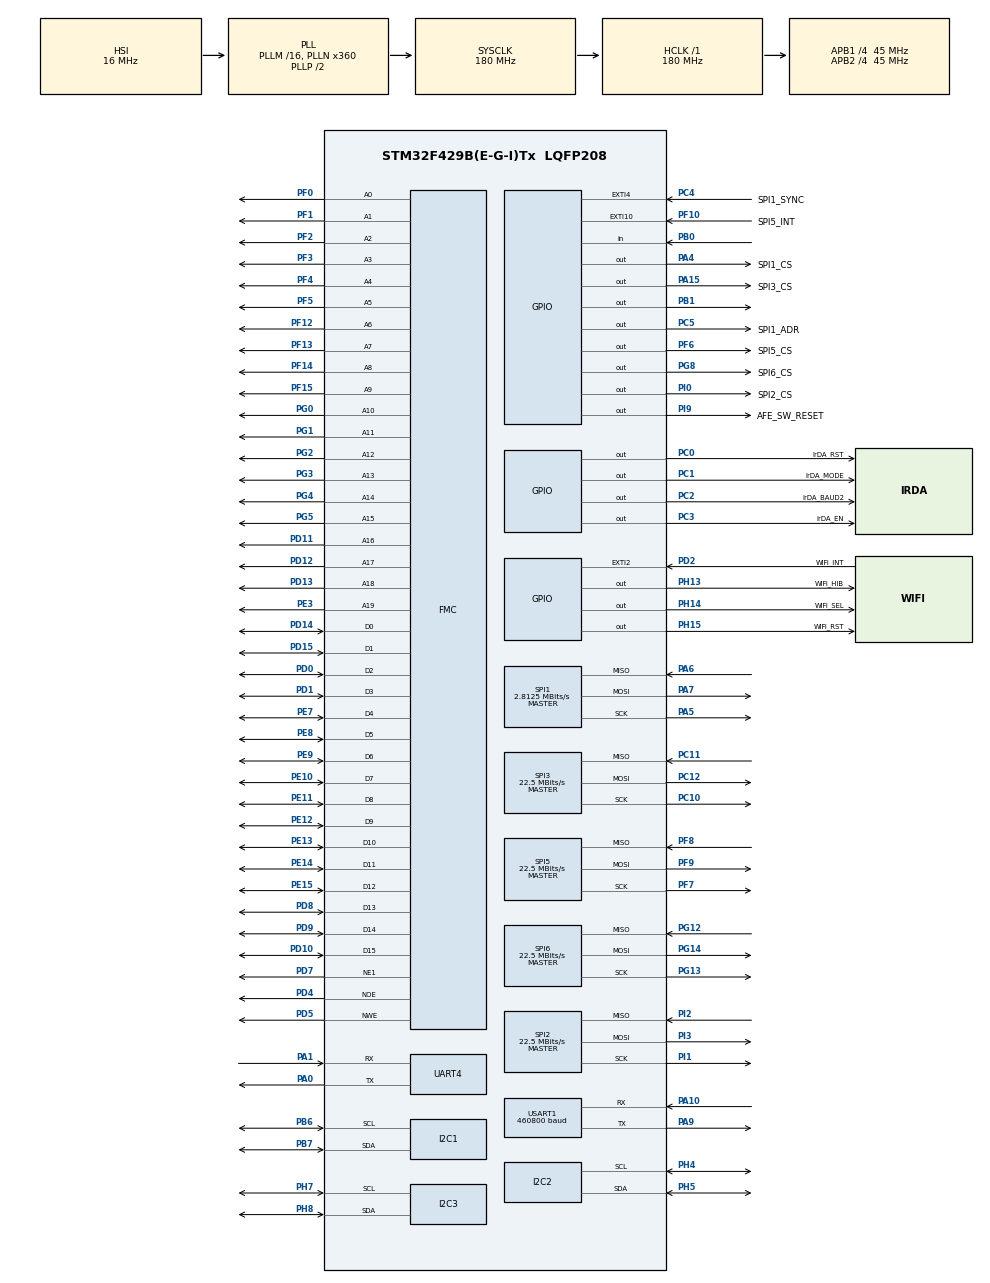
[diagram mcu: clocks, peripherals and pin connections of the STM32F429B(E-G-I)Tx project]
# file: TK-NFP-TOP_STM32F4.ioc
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Dma.I2C2_RX.0.Direction=DMA_PERIPH_TO_MEMORY
Dma.I2C2_RX.0.FIFOMode=DMA_FIFOMODE_DISABLE
Dma.I2C2_RX.0.Instance=DMA1_Stream3
Dma.I2C2_RX.0.MemDataAlignment=DMA_MDATAALIGN_BYTE
Dma.I2C2_RX.0.MemInc=DMA_MINC_ENABLE
Dma.I2C2_RX.0.Mode=DMA_NORMAL
Dma.I2C2_RX.0.PeriphDataAlignment=DMA_PDATAALIGN_BYTE
Dma.I2C2_RX.0.PeriphInc=DMA_PINC_DISABLE
Dma.I2C2_RX.0.Priority=DMA_PRIORITY_LOW
Dma.I2C2_TX.1.Direction=DMA_MEMORY_TO_PERIPH
Dma.I2C2_TX.1.FIFOMode=DMA_FIFOMODE_DISABLE
Dma.I2C2_TX.1.Instance=DMA1_Stream7
Dma.I2C2_TX.1.MemDataAlignment=DMA_MDATAALIGN_BYTE
Dma.I2C2_TX.1.MemInc=DMA_MINC_ENABLE
Dma.I2C2_TX.1.Mode=DMA_NORMAL
Dma.I2C2_TX.1.PeriphDataAlignment=DMA_PDATAALIGN_BYTE
Dma.I2C2_TX.1.PeriphInc=DMA_PINC_DISABLE
Dma.I2C2_TX.1.Priority=DMA_PRIORITY_HIGH
Dma.I2C3_RX.6.Direction=DMA_PERIPH_TO_MEMORY
Dma.I2C3_RX.6.FIFOMode=DMA_FIFOMODE_DISABLE
Dma.I2C3_RX.6.Instance=DMA1_Stream2
Dma.I2C3_RX.6.MemDataAlignment=DMA_MDATAALIGN_BYTE
Dma.I2C3_RX.6.MemInc=DMA_MINC_ENABLE
Dma.I2C3_RX.6.Mode=DMA_NORMAL
Dma.I2C3_RX.6.PeriphDataAlignment=DMA_PDATAALIGN_BYTE
Dma.I2C3_RX.6.PeriphInc=DMA_PINC_DISABLE
Dma.I2C3_RX.6.Priority=DMA_PRIORITY_HIGH
Dma.I2C3_TX.7.Direction=DMA_MEMORY_TO_PERIPH
Dma.I2C3_TX.7.FIFOMode=DMA_FIFOMODE_DISABLE
Dma.I2C3_TX.7.Instance=DMA1_Stream4
Dma.I2C3_TX.7.MemDataAlignment=DMA_MDATAALIGN_BYTE
Dma.I2C3_TX.7.MemInc=DMA_MINC_ENABLE
Dma.I2C3_TX.7.Mode=DMA_NORMAL
Dma.I2C3_TX.7.PeriphDataAlignment=DMA_PDATAALIGN_BYTE
Dma.I2C3_TX.7.PeriphInc=DMA_PINC_DISABLE
Dma.I2C3_TX.7.Priority=DMA_PRIORITY_LOW
Dma.Request0=I2C2_RX
Dma.Request1=I2C2_TX
Dma.Request2=USART1_RX
Dma.Request3=USART1_TX
Dma.Request4=SPI1_RX
Dma.Request5=SPI1_TX
Dma.Request6=I2C3_RX
Dma.Request7=I2C3_TX
Dma.SPI1_RX.4.Direction=DMA_PERIPH_TO_MEMORY
Dma.SPI1_RX.4.FIFOMode=DMA_FIFOMODE_DISABLE
Dma.SPI1_RX.4.Instance=DMA2_Stream0
Dma.SPI1_RX.4.MemDataAlignment=DMA_MDATAALIGN_BYTE
Dma.SPI1_RX.4.MemInc=DMA_MINC_ENABLE
Dma.SPI1_RX.4.Mode=DMA_NORMAL
Dma.SPI1_RX.4.PeriphDataAlignment=DMA_PDATAALIGN_BYTE
Dma.SPI1_RX.4.PeriphInc=DMA_PINC_DISABLE
Dma.SPI1_RX.4.Priority=DMA_PRIORITY_LOW
Dma.SPI1_TX.5.Direction=DMA_MEMORY_TO_PERIPH
Dma.SPI1_TX.5.FIFOMode=DMA_FIFOMODE_DISABLE
Dma.SPI1_TX.5.Instance=DMA2_Stream3
Dma.SPI1_TX.5.MemDataAlignment=DMA_MDATAALIGN_BYTE
Dma.SPI1_TX.5.MemInc=DMA_MINC_ENABLE
Dma.SPI1_TX.5.Mode=DMA_NORMAL
Dma.SPI1_TX.5.PeriphDataAlignment=DMA_PDATAALIGN_BYTE
Dma.SPI1_TX.5.PeriphInc=DMA_PINC_DISABLE
Dma.SPI1_TX.5.Priority=DMA_PRIORITY_LOW
Dma.USART1_RX.2.Direction=DMA_PERIPH_TO_MEMORY
Dma.USART1_RX.2.FIFOMode=DMA_FIFOMODE_DISABLE
Dma.USART1_RX.2.Instance=DMA2_Stream2
Dma.USART1_RX.2.MemDataAlignment=DMA_MDATAALIGN_BYTE
Dma.USART1_RX.2.MemInc=DMA_MINC_ENABLE
Dma.USART1_RX.2.Mode=DMA_NORMAL
Dma.USART1_RX.2.PeriphDataAlignment=DMA_PDATAALIGN_BYTE
Dma.USART1_RX.2.PeriphInc=DMA_PINC_DISABLE
Dma.USART1_RX.2.Priority=DMA_PRIORITY_LOW
Dma.USART1_TX.3.Direction=DMA_MEMORY_TO_PERIPH
Dma.USART1_TX.3.FIFOMode=DMA_FIFOMODE_DISABLE
Dma.USART1_TX.3.Instance=DMA2_Stream7
Dma.USART1_TX.3.MemDataAlignment=DMA_MDATAALIGN_BYTE
Dma.USART1_TX.3.MemInc=DMA_MINC_ENABLE
Dma.USART1_TX.3.Mode=DMA_NORMAL
Dma.USART1_TX.3.PeriphDataAlignment=DMA_PDATAALIGN_BYTE
Dma.USART1_TX.3.PeriphInc=DMA_PINC_DISABLE
Dma.USART1_TX.3.Priority=DMA_PRIORITY_HIGH
I2C2.I2C_Mode=I2C_Fast
I2C3.I2C_Mode=I2C_Fast
Mcu.Family=STM32F4
Mcu.Name=STM32F429B(E-G-I)Tx
Mcu.Package=LQFP208
NVIC.DMA1_Stream2_IRQn=true\:1\:0\:true\:false\:true\:false
NVIC.DMA1_Stream3_IRQn=true\:1\:3\:false\:false\:true\:false
NVIC.DMA1_Stream4_IRQn=true\:1\:1\:true\:false\:true\:false
NVIC.DMA1_Stream7_IRQn=true\:1\:2\:true\:false\:true\:false
NVIC.DMA2_Stream0_IRQn=true\:0\:0\:false\:false\:true\:false
NVIC.DMA2_Stream2_IRQn=true\:0\:1\:true\:false\:true\:false
NVIC.DMA2_Stream3_IRQn=true\:0\:0\:false\:false\:true\:false
NVIC.DMA2_Stream7_IRQn=true\:0\:0\:true\:false\:true\:false
NVIC.EXTI15_10_IRQn=true\:1\:0\:true\:false\:true\:true
NVIC.EXTI2_IRQn=true\:1\:0\:true\:false\:true\:true
NVIC.EXTI4_IRQn=true\:1\:0\:true\:false\:true\:true
NVIC.I2C2_EV_IRQn=true\:1\:0\:true\:false\:true\:true
NVIC.I2C3_EV_IRQn=true\:1\:0\:true\:false\:true\:true
NVIC.PriorityGroup=NVIC_PRIORITYGROUP_2
NVIC.SPI1_IRQn=true\:0\:0\:false\:false\:true\:true
NVIC.SPI5_IRQn=true\:1\:0\:true\:false\:true\:true
NVIC.SPI6_IRQn=true\:1\:0\:true\:false\:true\:true
NVIC.TIM1_TRG_COM_TIM11_IRQn=true\:1\:0\:true\:false\:true\:true
NVIC.TIM1_UP_TIM10_IRQn=true\:1\:0\:true\:false\:true\:true
NVIC.TIM7_IRQn=true\:1\:0\:true\:false\:true\:true
NVIC.TIM8_TRG_COM_TIM14_IRQn=true\:1\:0\:true\:false\:true\:true
NVIC.TIM8_UP_TIM13_IRQn=true\:1\:0\:true\:false\:true\:true
NVIC.UART4_IRQn=true\:1\:0\:true\:false\:true\:true
NVIC.USART1_IRQn=true\:1\:0\:true\:false\:true\:true
PA0/WKUP.Mode=Asynchronous
PA0/WKUP.Signal=UART4_TX
PA1.Mode=Asynchronous
PA1.Signal=UART4_RX
PA10.Mode=Asynchronous
PA10.Signal=USART1_RX
PA15.GPIO_Label=SPI3_CS
PA15.Signal=GPIO_Output
PA4.GPIO_Label=SPI1_CS
PA4.Signal=GPIO_Output
PA5.Mode=Full_Duplex_Master
PA5.Signal=SPI1_SCK
PA6.Mode=Full_Duplex_Master
PA6.Signal=SPI1_MISO
PA7.Mode=Full_Duplex_Master
PA7.Signal=SPI1_MOSI
PA9.Mode=Asynchronous
PA9.Signal=USART1_TX
PB0.Signal=GPIO_Input
PB1.Signal=GPIO_Output
PB6.Mode=I2C
PB6.Signal=I2C1_SCL
PB7.Mode=I2C
PB7.Signal=I2C1_SDA
PC0.GPIO_Label=IrDA_RST
PC0.Signal=GPIO_Output
PC1.GPIO_Label=IrDA_MODE
PC1.Signal=GPIO_Output
PC10.Mode=Full_Duplex_Master
PC10.Signal=SPI3_SCK
PC11.Mode=Full_Duplex_Master
PC11.Signal=SPI3_MISO
PC12.Mode=Full_Duplex_Master
PC12.Signal=SPI3_MOSI
PC2.GPIO_Label=IrDA_BAUD2
PC2.Signal=GPIO_Output
PC3.GPIO_Label=IrDA_EN
PC3.Signal=GPIO_Output
PC4.GPIO_Label=SPI1_SYNC
PC4.Signal=GPXTI4
PC5.GPIO_Label=SPI1_ADR
PC5.Signal=GPIO_Output
PD0.Signal=FMC_D2_DA2
PD1.Signal=FMC_D3_DA3
PD10.Signal=FMC_D15_DA15
PD11.Signal=FMC_A16_CLE
PD12.Signal=FMC_A17_ALE
PD13.Signal=FMC_A18
PD14.Signal=FMC_D0_DA0
PD15.Signal=FMC_D1_DA1
PD2.GPIO_Label=WiFi_INT
PD2.Signal=GPXTI2
PD4.Signal=FMC_NOE
PD5.Signal=FMC_NWE
PD7.Mode=NorPsramChipSelect1_1
PD7.Signal=FMC_NE1
PD8.Signal=FMC_D13_DA13
PD9.Signal=FMC_D14_DA14
PE10.Signal=FMC_D7_DA7
PE11.Signal=FMC_D8_DA8
PE12.Signal=FMC_D9_DA9
PE13.Signal=FMC_D10_DA10
PE14.Signal=FMC_D11_DA11
PE15.Signal=FMC_D12_DA12
PE3.Signal=FMC_A19
PE7.Signal=FMC_D4_DA4
PE8.Signal=FMC_D5_DA5
PE9.Signal=FMC_D6_DA6
PF0.Signal=FMC_A0
PF1.Signal=FMC_A1
PF10.GPIO_Label=SPI5_INT
PF10.Signal=GPXTI10
PF12.Signal=FMC_A6
PF13.Signal=FMC_A7
PF14.Signal=FMC_A8
PF15.Signal=FMC_A9
PF2.Signal=FMC_A2
PF3.Signal=FMC_A3
PF4.Signal=FMC_A4
PF5.Signal=FMC_A5
PF6.GPIO_Label=SPI5_CS
PF6.Signal=GPIO_Output
PF7.Mode=Full_Duplex_Master
PF7.Signal=SPI5_SCK
PF8.Mode=Full_Duplex_Master
PF8.Signal=SPI5_MISO
PF9.Mode=Full_Duplex_Master
PF9.Signal=SPI5_MOSI
PG0.Signal=FMC_A10
PG1.Signal=FMC_A11
PG12.Mode=Full_Duplex_Master
PG12.Signal=SPI6_MISO
PG13.Mode=Full_Duplex_Master
PG13.Signal=SPI6_SCK
PG14.Mode=Full_Duplex_Master
PG14.Signal=SPI6_MOSI
PG2.Signal=FMC_A12
PG3.Signal=FMC_A13
PG4.Signal=FMC_A14_BA0
PG5.Signal=FMC_A15_BA1
PG8.GPIO_Label=SPI6_CS
PG8.Signal=GPIO_Output
PH13.GPIO_Label=WiFi_HIB
PH13.Signal=GPIO_Output
PH14.GPIO_Label=WiFi_SEL
PH14.Signal=GPIO_Output
PH15.GPIO_Label=WiFi_RST
PH15.Signal=GPIO_Output
PH4.Mode=I2C
PH4.Signal=I2C2_SCL
PH5.Mode=I2C
PH5.Signal=I2C2_SDA
PH7.Mode=I2C
PH7.Signal=I2C3_SCL
PH8.Mode=I2C
PH8.Signal=I2C3_SDA
PI0.GPIO_Label=SPI2_CS
PI0.Signal=GPIO_Output
PI1.Mode=Full_Duplex_Master
PI1.Signal=SPI2_SCK
PI2.Mode=Full_Duplex_Master
PI2.Signal=SPI2_MISO
PI3.Mode=Full_Duplex_Master
PI3.Signal=SPI2_MOSI
PI9.GPIO_Label=AFE_SW_RESET
PI9.Signal=GPIO_Output
ProjectManager.HeapSize=0x200
ProjectManager.StackSize=0x400
ProjectManager.TargetToolchain=Other Toolchains (GPDSC)
RCC.48MHZClocksFreq_Value=90000000
RCC.AHBFreq_Value=180000000
RCC.APB1CLKDivider=RCC_HCLK_DIV4
RCC.APB1Freq_Value=45000000
RCC.APB1TimFreq_Value=90000000
RCC.APB2CLKDivider=RCC_HCLK_DIV4
RCC.APB2Freq_Value=45000000
RCC.APB2TimFreq_Value=90000000
RCC.CortexFreq_Value=180000000
RCC.HCLKFreq_Value=180000000
RCC.HSE_VALUE=25000000
RCC.HSI_VALUE=16000000
RCC.LSE_VALUE=32768
RCC.PLLN=360
RCC.SYSCLKFreq_VALUE=180000000
RCC.SYSCLKSource=RCC_SYSCLKSOURCE_PLLCLK
RCC.VCOOutputFreq_Value=360000000
SH.FMC_A0.0=FMC_A0,20b-a1
SH.FMC_A1.0=FMC_A1,20b-a1
SH.FMC_A10.0=FMC_A10,20b-a1
SH.FMC_A11.0=FMC_A11,20b-a1
SH.FMC_A12.0=FMC_A12,20b-a1
SH.FMC_A13.0=FMC_A13,20b-a1
SH.FMC_A14_BA0.0=FMC_A14,20b-a1
SH.FMC_A15_BA1.0=FMC_A15,20b-a1
SH.FMC_A16_CLE.0=FMC_A16,20b-a1
SH.FMC_A17_ALE.0=FMC_A17,20b-a1
SH.FMC_A18.0=FMC_A18,20b-a1
SH.FMC_A19.0=FMC_A19,20b-a1
SH.FMC_A2.0=FMC_A2,20b-a1
SH.FMC_A3.0=FMC_A3,20b-a1
SH.FMC_A4.0=FMC_A4,20b-a1
SH.FMC_A5.0=FMC_A5,20b-a1
SH.FMC_A6.0=FMC_A6,20b-a1
SH.FMC_A7.0=FMC_A7,20b-a1
SH.FMC_A8.0=FMC_A8,20b-a1
SH.FMC_A9.0=FMC_A9,20b-a1
SH.FMC_D0_DA0.0=FMC_D0,16b-d1
SH.FMC_D10_DA10.0=FMC_D10,16b-d1
SH.FMC_D11_DA11.0=FMC_D11,16b-d1
SH.FMC_D12_DA12.0=FMC_D12,16b-d1
SH.FMC_D13_DA13.0=FMC_D13,16b-d1
SH.FMC_D14_DA14.0=FMC_D14,16b-d1
SH.FMC_D15_DA15.0=FMC_D15,16b-d1
SH.FMC_D1_DA1.0=FMC_D1,16b-d1
SH.FMC_D2_DA2.0=FMC_D2,16b-d1
SH.FMC_D3_DA3.0=FMC_D3,16b-d1
SH.FMC_D4_DA4.0=FMC_D4,16b-d1
SH.FMC_D5_DA5.0=FMC_D5,16b-d1
SH.FMC_D6_DA6.0=FMC_D6,16b-d1
SH.FMC_D7_DA7.0=FMC_D7,16b-d1
SH.FMC_D8_DA8.0=FMC_D8,16b-d1
SH.FMC_D9_DA9.0=FMC_D9,16b-d1
SH.FMC_NOE.0=FMC_NOE,Sram1
SH.FMC_NWE.0=FMC_NWE,Sram1
SPI1.BaudRatePrescaler=SPI_BAUDRATEPRESCALER_16
SPI1.CLKPhase=SPI_PHASE_2EDGE
SPI1.CLKPolarity=SPI_POLARITY_HIGH
SPI1.CalculateBaudRate=2.8125 MBits/s
SPI1.Direction=SPI_DIRECTION_2LINES
SPI1.Mode=SPI_MODE_MASTER
SPI1.VirtualType=VM_MASTER
SPI2.BaudRatePrescaler=SPI_BAUDRATEPRESCALER_2
SPI2.CalculateBaudRate=22.5 MBits/s
SPI2.Direction=SPI_DIRECTION_2LINES
SPI2.Mode=SPI_MODE_MASTER
SPI2.VirtualType=VM_MASTER
SPI3.BaudRatePrescaler=SPI_BAUDRATEPRESCALER_2
SPI3.CalculateBaudRate=22.5 MBits/s
SPI3.Direction=SPI_DIRECTION_2LINES
SPI3.Mode=SPI_MODE_MASTER
SPI3.VirtualType=VM_MASTER
SPI5.BaudRatePrescaler=SPI_BAUDRATEPRESCALER_2
SPI5.CalculateBaudRate=22.5 MBits/s
SPI5.Direction=SPI_DIRECTION_2LINES
SPI5.Mode=SPI_MODE_MASTER
SPI5.VirtualType=VM_MASTER
SPI6.BaudRatePrescaler=SPI_BAUDRATEPRESCALER_2
SPI6.CalculateBaudRate=22.5 MBits/s
SPI6.Direction=SPI_DIRECTION_2LINES
SPI6.Mode=SPI_MODE_MASTER
SPI6.VirtualType=VM_MASTER
TIM10.Period=6
TIM10.Prescaler=45000
TIM11.Period=10000
TIM11.Prescaler=1300
TIM13.Period=100
TIM13.Prescaler=45000
TIM7.Period=500
TIM7.Prescaler=24
UART4.VirtualMode=Asynchronous
USART1.BaudRate=460800
USART1.VirtualMode=VM_ASYNC
VP_TIM10_VS_ClockSourceINT.Mode=Enable_Timer
VP_TIM11_VS_ClockSourceINT.Mode=Enable_Timer
VP_TIM13_VS_ClockSourceINT.Mode=Enable_Timer
VP_TIM14_VS_ClockSourceINT.Mode=Enable_Timer
VP_TIM7_VS_ClockSourceINT.Mode=Enable_Timer
board=TK-NFP-TOP_STM32F4

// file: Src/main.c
/**
  ******************************************************************************
  * @file           : main.c
  * @brief          : Main program body
  ******************************************************************************
  ** This notice applies to any and all portions of this file
  * that are not between comment pairs USER CODE BEGIN and
  * USER CODE END. Other portions of this file, whether
  * inserted by the user or by software development tools
  * are owned by their respective copyright owners.
  *
  * COPYRIGHT(c) 2018 STMicroelectronics
  *
  * Redistribution and use in source and binary forms, with or without modification,
  * are permitted provided that the following conditions are met:
  *   1. Redistributions of source code must retain the above copyright notice,
  *      this list of conditions and the following disclaimer.
  *   2. Redistributions in binary form must reproduce the above copyright notice,
  *      this list of conditions and the following disclaimer in the documentation
  *      and/or other materials provided with the distribution.
  *   3. Neither the name of STMicroelectronics nor the names of its contributors
  *      may be used to endorse or promote products derived from this software
  *      without specific prior written permission.
  *
  * THIS SOFTWARE IS PROVIDED BY THE COPYRIGHT HOLDERS AND CONTRIBUTORS "AS IS"
  * AND ANY EXPRESS OR IMPLIED WARRANTIES, INCLUDING, BUT NOT LIMITED TO, THE
  * IMPLIED WARRANTIES OF MERCHANTABILITY AND FITNESS FOR A PARTICULAR PURPOSE ARE
  * DISCLAIMED. IN NO EVENT SHALL THE COPYRIGHT HOLDER OR CONTRIBUTORS BE LIABLE
  * FOR ANY DIRECT, INDIRECT, INCIDENTAL, SPECIAL, EXEMPLARY, OR CONSEQUENTIAL
  * DAMAGES (INCLUDING, BUT NOT LIMITED TO, PROCUREMENT OF SUBSTITUTE GOODS OR
  * SERVICES; LOSS OF USE, DATA, OR PROFITS; OR BUSINESS INTERRUPTION) HOWEVER
  * CAUSED AND ON ANY THEORY OF LIABILITY, WHETHER IN CONTRACT, STRICT LIABILITY,
  * OR TORT (INCLUDING NEGLIGENCE OR OTHERWISE) ARISING IN ANY WAY OUT OF THE USE
  * OF THIS SOFTWARE, EVEN IF ADVISED OF THE POSSIBILITY OF SUCH DAMAGE.
  *
  ******************************************************************************
  */
#include "main.h"
#include "stm32f4xx_hal.h"
#include "dma.h"
#include "i2c.h"
#include "spi.h"
#include "tim.h"
#include "usart.h"
#include "gpio.h"
#include "fmc.h"

/* USER CODE BEGIN Includes */
#include "Handler.h"
#include "ExtFunctions.h"
#include "AD7190.h"

/* USER CODE END Includes */

/* USER CODE BEGIN PV */
/* Private variables ---------------------------------------------------------*/
uint8_t usart1BufRx[1];
uint8_t I2C2_TRANSMIT_STARTED = 0;
uint8_t I2C2_TRANSMIT_ENDED = 0;
/* USER CODE END PV */

void SystemClock_Config(void);

/* USER CODE BEGIN PFP */
/* Private function prototypes -----------------------------------------------*/

/* USER CODE END PFP */

int main(void)
{

  /* MCU Configuration----------------------------------------------------------*/

  /* Reset of all peripherals, Initializes the Flash interface and the Systick. */
  HAL_Init();

  /* Configure the system clock */
  SystemClock_Config();

  /* Initialize all configured peripherals */
  MX_GPIO_Init();
  MX_DMA_Init();
  MX_USART1_UART_Init();
  MX_UART4_Init();
  MX_SPI1_Init();
  MX_SPI2_Init();
  MX_SPI3_Init();
  MX_SPI5_Init();
  MX_SPI6_Init();
  MX_TIM14_Init();
  MX_TIM13_Init();
  MX_I2C1_Init();
  MX_I2C2_Init();
  MX_I2C3_Init();
  MX_FMC_Init();
  MX_TIM7_Init();
  MX_TIM10_Init();
  MX_TIM11_Init();
  /* USER CODE BEGIN 2 */
    SPI6_CS_UP
    InitHandler(POLYGRAPH);
    EEGRecorderInit(1,250);
    WriteMem(REG_LOG_LVL, 7);
    WriteMem(REG_Simple_link, 1);
    WriteMem(REG_EEG_Auto_Band, 0);
    WriteMem(REG_ADC_REG1,0x00000001);
    WriteMem(REG_ADC_REG2,0x00000001);
    WriteMem(REG_ADC_REG3,0x00000004);
    usart1BufRx[0] = 0x00;
    HAL_UART_Receive_DMA(&huart1, usart1BufRx, 1);
    HAL_TIM_Base_Start_IT(&htim7);
    HAL_TIM_Base_Start_IT(&htim10);
    HAL_TIM_Base_Start_IT(&htim11);

//    AD7190_Reset();
    unsigned long samplesAverage = 0x0;
    unsigned long chn = 0x0;
//    samplesAverage = AD7190_GetRegisterValue(AD7190_REG_STAT, 1, 1, 1);
//    chn=sprintf(buffer,"AD7190_REG_STAT %08X",samplesAverage);
//    HAL_UART_Transmit(&huart1, buffer, chn, 10000);
//    HAL_Delay(1000);
//    samplesAverage = AD7190_GetRegisterValue(AD7190_REG_MODE, 3, 1, 1);
//    chn=sprintf(buffer,"AD7190_REG_MODE %08X",samplesAverage);
//    HAL_UART_Transmit(&huart1, buffer, chn, 10000);
//    HAL_Delay(1000);
//    samplesAverage = AD7190_GetRegisterValue(AD7190_REG_CONF, 3, 1, 1);
//    chn=sprintf(buffer,"AD7190_REG_CONF %08X",samplesAverage);
//    HAL_UART_Transmit(&huart1, buffer, chn, 10000);
//    HAL_Delay(1000);
//    samplesAverage = AD7190_GetRegisterValue(AD7190_REG_DATA, 3, 1, 1);
//    chn=sprintf(buffer,"AD7190_REG_DATA %08X",samplesAverage);
//    HAL_UART_Transmit(&huart1, buffer, chn, 10000);
//    HAL_Delay(1000);
//    samplesAverage = AD7190_GetRegisterValue(AD7190_REG_ID, 1, 1, 1);
//    chn=sprintf(buffer,"AD7190_REG_ID %08X",samplesAverage);
//    HAL_UART_Transmit(&huart1, buffer, chn, 10000);
//    HAL_Delay(1000);
//    samplesAverage = AD7190_GetRegisterValue(AD7190_REG_GPOCON, 1, 1, 1);
//    chn=sprintf(buffer,"AD7190_REG_GPOCON %08X",samplesAverage);
//    HAL_UART_Transmit(&huart1, buffer, chn, 10000);
//    HAL_Delay(1000);
//    samplesAverage = AD7190_GetRegisterValue(AD7190_REG_OFFSET, 3, 1, 1);
//    chn=sprintf(buffer,"AD7190_REG_OFFSET %08X",samplesAverage);
//    HAL_UART_Transmit(&huart1, buffer, chn, 10000);
//    HAL_Delay(1000);
//    samplesAverage = AD7190_GetRegisterValue(AD7190_REG_FULLSCALE, 3, 1, 1);
//    chn=sprintf(buffer,"AD7190_REG_FULLSCALE %08X",samplesAverage);
//    HAL_UART_Transmit(&huart1, buffer, chn, 10000);
//    HAL_Delay(1000);

//    AD7190_SetPower(1);
    if (AD7190_Init() == 1)
    {
        AD7190_SetLeds(2);
        HAL_UART_Transmit(&huart1, "AD7190 found", 12, 10000);
    }
    else
    {
        AD7190_SetLeds(0);
        HAL_UART_Transmit(&huart1, "AD7190 not found", 16, 10000);
    }
//    HAL_SPI_Transmit_DMA(&hspi1, "-----", 5);
//    AD7190_RangeSetup(1,AD7190_CONF_GAIN_1);
//    AD7190_ChannelSelect(AD7190_CH_AIN1P_AINCOM);
//    CommandLineInterpreter("/get/memory?ip=192.168.1.3&port=5683");

//        HAL_UART_Transmit(&huart1, "test2", 5, 10000);
    WriteMem(REG_Led_Ch_T1,1);
    WriteMem(REG_Led_Ch_T2,2);
    WriteMem(REG_Led_Ch_T3,4);
    WriteMem(REG_Led_Q_T1_Red,100);
    WriteMem(REG_Led_Q_T1_Green,1);
    WriteMem(REG_Led_Q_T1_Blue,1);
    WriteMem(REG_Led_Q_T2_Red,1);
    WriteMem(REG_Led_Q_T2_Green,100);
    WriteMem(REG_Led_Q_T2_Blue,1);
    WriteMem(REG_Led_Q_T3_Red,1);
    WriteMem(REG_Led_Q_T3_Green,1);
    WriteMem(REG_Led_Q_T3_Blue,100);

    AFE_MUX_IMP_init();

  /* USER CODE END 2 */

  /* Infinite loop */
  /* USER CODE BEGIN WHILE */
//    AD7190_GetRegisterValue(AD7190_REG_ID, 1, 1, 0);
//    initiateConversionCycle();
//    HAL_SPI_Transmit_DMA(&hspi1, "-----", 5);
//    initiateDMATestCycle();
//    AD7190_SetLeds(2);
    AD7190_ContinuousReadStart();
    unsigned char i=0;
//    HAL_UART_Transmit(&huart1, "Check", 5, 10000);
//    HAL_Delay(1000);
//    samplesAverage = AD7190_GetRegisterValue(AD7190_REG_STAT, 1, 1, 1);
//    chn=sprintf(buffer,"AD7190_REG_STAT %08X",samplesAverage);
//    HAL_UART_Transmit(&huart1, buffer, chn, 10000);
//    HAL_Delay(1000);
//    samplesAverage = AD7190_GetRegisterValue(AD7190_REG_MODE, 3, 1, 1);
//    chn=sprintf(buffer,"AD7190_REG_MODE %08X",samplesAverage);
//    HAL_UART_Transmit(&huart1, buffer, chn, 10000);
//    HAL_Delay(1000);
//    samplesAverage = AD7190_GetRegisterValue(AD7190_REG_CONF, 3, 1, 1);
//    chn=sprintf(buffer,"AD7190_REG_CONF %08X",samplesAverage);
//    HAL_UART_Transmit(&huart1, buffer, chn, 10000);
//    HAL_Delay(1000);
//    samplesAverage = AD7190_GetRegisterValue(AD7190_REG_DATA, 3, 1, 1);
//    chn=sprintf(buffer,"AD7190_REG_DATA %08X",samplesAverage);
//    HAL_UART_Transmit(&huart1, buffer, chn, 10000);
//    HAL_Delay(1000);
//    samplesAverage = AD7190_GetRegisterValue(AD7190_REG_ID, 1, 1, 1);
//    chn=sprintf(buffer,"AD7190_REG_ID %08X",samplesAverage);
//    HAL_UART_Transmit(&huart1, buffer, chn, 10000);
//    HAL_Delay(1000);
//    samplesAverage = AD7190_GetRegisterValue(AD7190_REG_GPOCON, 1, 1, 1);
//    chn=sprintf(buffer,"AD7190_REG_GPOCON %08X",samplesAverage);
//    HAL_UART_Transmit(&huart1, buffer, chn, 10000);
//    HAL_Delay(1000);
//    samplesAverage = AD7190_GetRegisterValue(AD7190_REG_OFFSET, 3, 1, 1);
//    chn=sprintf(buffer,"AD7190_REG_OFFSET %08X",samplesAverage);
//    HAL_UART_Transmit(&huart1, buffer, chn, 10000);
//    HAL_Delay(1000);
//    samplesAverage = AD7190_GetRegisterValue(AD7190_REG_FULLSCALE, 3, 1, 1);
//    chn=sprintf(buffer,"AD7190_REG_FULLSCALE %08X",samplesAverage);
//    HAL_UART_Transmit(&huart1, buffer, chn, 10000);

    HAL_Delay(3000);
    HAL_TIM_Base_Start_IT(&htim14);
    HAL_UART_Transmit(&huart1, "\n\r\nStart!\n\r\n", 12, 1000);
    while (1)
    {
      UserOperationHandler();
      UserProtocolHandler();

//      if (observerConversionCycle())
//        initiateConversionCycle();

  /* USER CODE END WHILE */

  /* USER CODE BEGIN 3 */
//    WriteMem(REG_ADC_CH1,AD7190_ContinuousRead());
    }
  /* USER CODE END 3 */

}

void SystemClock_Config(void)
{

  RCC_OscInitTypeDef RCC_OscInitStruct;
  RCC_ClkInitTypeDef RCC_ClkInitStruct;

    /**Configure the main internal regulator output voltage
    */
  __HAL_RCC_PWR_CLK_ENABLE();

  __HAL_PWR_VOLTAGESCALING_CONFIG(PWR_REGULATOR_VOLTAGE_SCALE1);

    /**Initializes the CPU, AHB and APB busses clocks
    */
  RCC_OscInitStruct.OscillatorType = RCC_OSCILLATORTYPE_HSI;
  RCC_OscInitStruct.HSIState = RCC_HSI_ON;
  RCC_OscInitStruct.HSICalibrationValue = 16;
  RCC_OscInitStruct.PLL.PLLState = RCC_PLL_ON;
  RCC_OscInitStruct.PLL.PLLSource = RCC_PLLSOURCE_HSI;
  RCC_OscInitStruct.PLL.PLLM = 16;
  RCC_OscInitStruct.PLL.PLLN = 360;
  RCC_OscInitStruct.PLL.PLLP = RCC_PLLP_DIV2;
  RCC_OscInitStruct.PLL.PLLQ = 4;
  if (HAL_RCC_OscConfig(&RCC_OscInitStruct) != HAL_OK)
  {
    _Error_Handler(__FILE__, __LINE__);
  }

    /**Activate the Over-Drive mode
    */
  if (HAL_PWREx_EnableOverDrive() != HAL_OK)
  {
    _Error_Handler(__FILE__, __LINE__);
  }

    /**Initializes the CPU, AHB and APB busses clocks
    */
  RCC_ClkInitStruct.ClockType = RCC_CLOCKTYPE_HCLK|RCC_CLOCKTYPE_SYSCLK
                              |RCC_CLOCKTYPE_PCLK1|RCC_CLOCKTYPE_PCLK2;
  RCC_ClkInitStruct.SYSCLKSource = RCC_SYSCLKSOURCE_PLLCLK;
  RCC_ClkInitStruct.AHBCLKDivider = RCC_SYSCLK_DIV1;
  RCC_ClkInitStruct.APB1CLKDivider = RCC_HCLK_DIV4;
  RCC_ClkInitStruct.APB2CLKDivider = RCC_HCLK_DIV4;

  if (HAL_RCC_ClockConfig(&RCC_ClkInitStruct, FLASH_LATENCY_5) != HAL_OK)
  {
    _Error_Handler(__FILE__, __LINE__);
  }

    /**Configure the Systick interrupt time
    */
  HAL_SYSTICK_Config(HAL_RCC_GetHCLKFreq()/1000);

    /**Configure the Systick
    */
  HAL_SYSTICK_CLKSourceConfig(SYSTICK_CLKSOURCE_HCLK);

  /* SysTick_IRQn interrupt configuration */
  HAL_NVIC_SetPriority(SysTick_IRQn, 0, 0);
}

/* USER CODE BEGIN 4 */
void HAL_I2C_MemRxCpltCallback(I2C_HandleTypeDef *hi2c)
{
	if(hi2c->Instance == I2C2)
	{
		I2C2_TRANSMIT_ENDED = 1;
	}
}

void HAL_I2C_MemTxCpltCallback(I2C_HandleTypeDef *hi2c)
{
	if(hi2c->Instance == I2C2)
	{
		I2C2_TRANSMIT_ENDED = 1;
	}
}

void HAL_I2C_MasterTxCpltCallback(I2C_HandleTypeDef *hi2c)
{
	if(hi2c->Instance == I2C2)
	{
		I2C2_TRANSMIT_ENDED = 1;
	}
}

void HAL_I2C_MasterRxCpltCallback(I2C_HandleTypeDef *hi2c)
{
	if(hi2c->Instance == I2C2)
	{
		I2C2_TRANSMIT_ENDED = 1;
	}
}
void HAL_TIM_PeriodElapsedCallback(TIM_HandleTypeDef *htim)
{
	if(htim->Instance == TIM13)
	{
		AFEMUX_timer_callback();
	}

	if(htim->Instance == TIM14)
	{
		//IMP_timer_callback();
	}
}
/* USER CODE END 4 */

void _Error_Handler(char *file, int line)
{
  /* USER CODE BEGIN Error_Handler_Debug */
  /* User can add his own implementation to report the HAL error return state */
//  while(1)
//  {
//  }
  /* USER CODE END Error_Handler_Debug */
}

/************************ (C) COPYRIGHT STMicroelectronics *****END OF FILE****/
